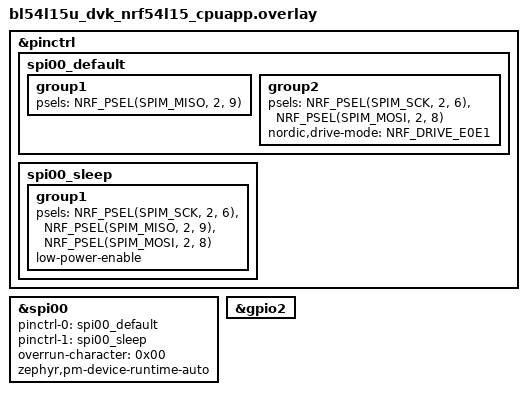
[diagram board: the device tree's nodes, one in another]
/*
 * Copyright (c) 2024 Nordic Semiconductor ASA
 * Copyright (c) 2025 Ezurio LLC
 *
 * SPDX-License-Identifier: Apache-2.0
 */

&pinctrl {
	spi00_default: spi00_default {
		group1 {
			psels = <NRF_PSEL(SPIM_MISO, 2, 9)>;
		};

		group2 {
			psels = <NRF_PSEL(SPIM_SCK, 2, 6)>,
				<NRF_PSEL(SPIM_MOSI, 2, 8)>;
			nordic,drive-mode = <NRF_DRIVE_E0E1>;
		};
	};

	spi00_sleep: spi00_sleep {
		group1 {
			psels = <NRF_PSEL(SPIM_SCK, 2, 6)>,
				<NRF_PSEL(SPIM_MISO, 2, 9)>,
				<NRF_PSEL(SPIM_MOSI, 2, 8)>;
			low-power-enable;
		};
	};
};

/delete-node/ &mx25r64;

#define SPI_LOOPBACK_SLOW_HZ DT_FREQ_M(2)
#define SPI_LOOPBACK_FAST_HZ DT_FREQ_M(4)

spi_loopback: &spi00 {
	status = "okay";
	pinctrl-0 = <&spi00_default>;
	pinctrl-1 = <&spi00_sleep>;
	pinctrl-names = "default", "sleep";
	overrun-character = <0x00>;
	zephyr,pm-device-runtime-auto;
};

&gpio2 {
	status = "okay";
};

#include "../spi-loopback.dtsi"
